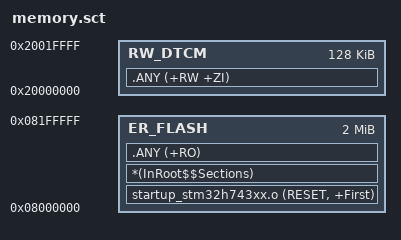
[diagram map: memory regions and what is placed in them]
; Internal flash and DTCM only. DMA must NOT use this DTCM data region.
LR_FLASH 0x08000000 0x00200000 {
  ER_FLASH 0x08000000 0x00200000 {
    startup_stm32h743xx.o (RESET, +First)
    *(InRoot$$Sections)
    .ANY (+RO)
  }
  RW_DTCM 0x20000000 0x00020000 {
    .ANY (+RW +ZI)
  }
}
